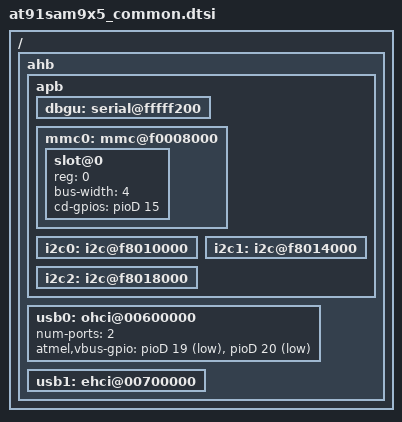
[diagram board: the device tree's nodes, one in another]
/*
 * at91sam9x5_common.dtsi - Device Tree Include file for AT91SAM9x5 Evaluation Kit:
 *                          common peripherals.
 *
 *  Copyright (C) 2012 Atmel,
 *                2012 Nicolas Ferre <nicolas.ferre@atmel.com>
 *
 * Licensed under GPLv2 or later.
 */
/include/ "at91sam9x5.dtsi"
/include/ "at91sam9x5cm.dtsi"

/ {
	ahb {
		apb {
			dbgu: serial@fffff200 {
				status = "okay";
			};

			mmc0: mmc@f0008000 {
				status = "okay";
				slot@0 {
					reg = <0>;
					bus-width = <4>;
					cd-gpios = <&pioD 15 0>;
				};
			};

			i2c0: i2c@f8010000 {
				status = "okay";
			};

			i2c1: i2c@f8014000 {
				status = "okay";
			};

			i2c2: i2c@f8018000 {
				status = "okay";
			};
		};

		usb0: ohci@00600000 {
			status = "okay";
			num-ports = <2>;
			atmel,vbus-gpio = <&pioD 19 1
					   &pioD 20 1
					  >;
		};

		usb1: ehci@00700000 {
			status = "okay";
		};
	};
};
